AUTOSAR XML (schema 314)
package /ComponentType
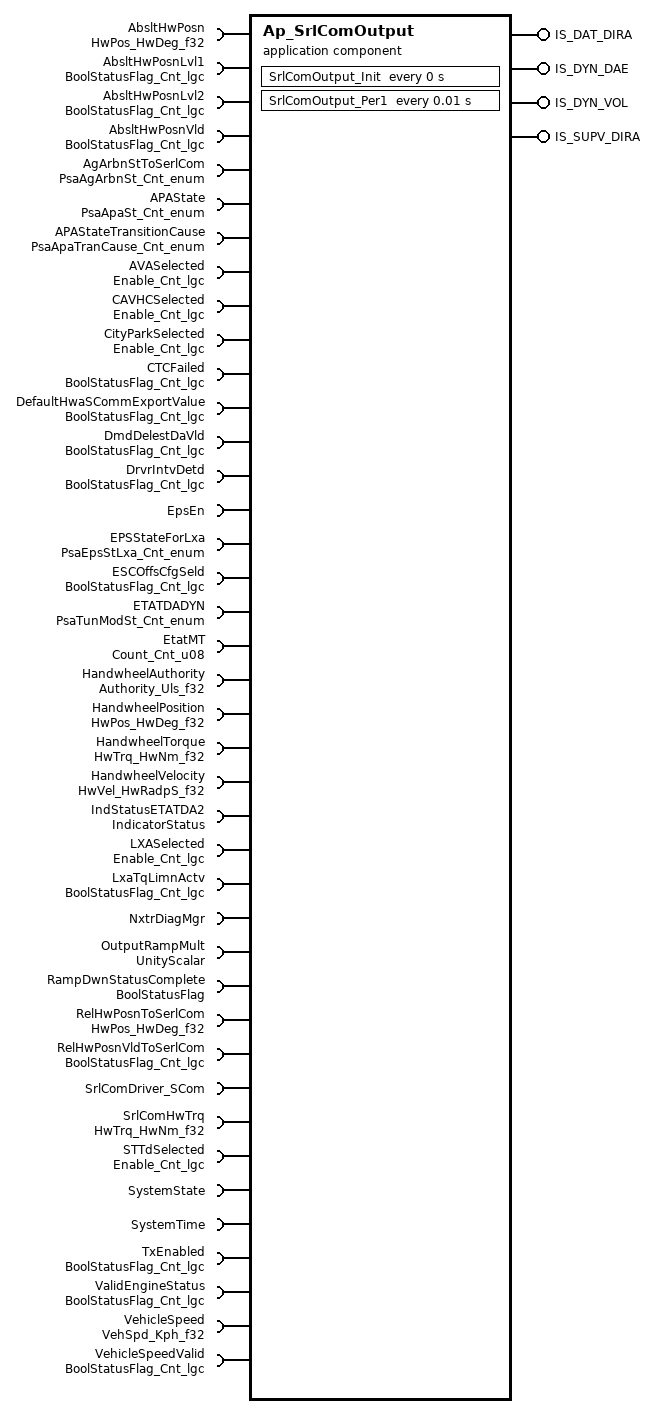
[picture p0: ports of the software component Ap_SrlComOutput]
  application software component type Ap_SrlComOutput
    4 x provide port, all with server-com-spec{operation=Get, queue-length=1}:
      IS_DAT_DIRA: provided-interface=IS_DAT_DIRA
      IS_DYN_DAE: provided-interface=IS_DYN_DAE
      IS_DYN_VOL: provided-interface=IS_DYN_VOL
      IS_SUPV_DIRA: provided-interface=IS_SUPV_DIRA
    40 x require port:
      AbsltHwPosn: unqueued-receiver-com-spec{data-element=HwDeg_f32, init-value=D_ZERO_ULS_F32}, required-interface=HwPos_HwDeg_f32
      AbsltHwPosnLvl1: unqueued-receiver-com-spec{data-element=Cnt_lgc, init-value=D_FALSE_CNT_LGC}, required-interface=BoolStatusFlag_Cnt_lgc
      AbsltHwPosnLvl2: unqueued-receiver-com-spec{data-element=Cnt_lgc, init-value=D_FALSE_CNT_LGC}, required-interface=BoolStatusFlag_Cnt_lgc
      AbsltHwPosnVld: unqueued-receiver-com-spec{data-element=Cnt_lgc, init-value=D_FALSE_CNT_LGC}, required-interface=BoolStatusFlag_Cnt_lgc
      AgArbnStToSerlCom: unqueued-receiver-com-spec{data-element=Cnt_enum, init-value=D_PSAAGARBNSTINIT_CNT_ENUM}, required-interface=PsaAgArbnSt_Cnt_enum
      APAState: unqueued-receiver-com-spec{data-element=Cnt_enum, init-value=D_PSAAPASTINIT_CNT_ENUM}, required-interface=PsaApaSt_Cnt_enum
      APAStateTransitionCause: unqueued-receiver-com-spec{data-element=Cnt_enum, init-value=D_PSAAPATRANCAUSEINIT_CNT_ENUM}, required-interface=PsaApaTranCause_Cnt_enum
      AVASelected: unqueued-receiver-com-spec{data-element=Cnt_lgc, init-value=D_FALSE_CNT_LGC}, required-interface=Enable_Cnt_lgc
      CAVHCSelected: unqueued-receiver-com-spec{data-element=Cnt_lgc, init-value=D_FALSE_CNT_LGC}, required-interface=Enable_Cnt_lgc
      CityParkSelected: unqueued-receiver-com-spec{data-element=Cnt_lgc, init-value=D_FALSE_CNT_LGC}, required-interface=Enable_Cnt_lgc
      CTCFailed: unqueued-receiver-com-spec{data-element=Cnt_lgc, init-value=D_FALSE_CNT_LGC}, required-interface=BoolStatusFlag_Cnt_lgc
      DefaultHwaSCommExportValue: unqueued-receiver-com-spec{data-element=Cnt_lgc, init-value=D_FALSE_CNT_LGC}, required-interface=BoolStatusFlag_Cnt_lgc
      DmdDelestDaVld: unqueued-receiver-com-spec{data-element=Cnt_lgc, init-value=D_FALSE_CNT_LGC}, required-interface=BoolStatusFlag_Cnt_lgc
      DrvrIntvDetd: unqueued-receiver-com-spec{data-element=Cnt_lgc, init-value=D_FALSE_CNT_LGC}, required-interface=BoolStatusFlag_Cnt_lgc
      EpsEn: client-com-spec=OP_GET, required-interface=EpsEn
      EPSStateForLxa: unqueued-receiver-com-spec{data-element=Cnt_enum, init-value=D_PSAEPSSTLXAINIT_CNT_ENUM}, required-interface=PsaEpsStLxa_Cnt_enum
      ESCOffsCfgSeld: unqueued-receiver-com-spec{data-element=Cnt_lgc, init-value=D_FALSE_CNT_LGC}, required-interface=BoolStatusFlag_Cnt_lgc
      ETATDADYN: unqueued-receiver-com-spec{data-element=Cnt_enum, init-value=D_PSATUNMODSTINIT_CNT_ENUM}, required-interface=PsaTunModSt_Cnt_enum
      EtatMT: unqueued-receiver-com-spec{data-element=Cnt_u08, init-value=D_ZERO_CNT_U8}, required-interface=Count_Cnt_u08
      HandwheelAuthority: unqueued-receiver-com-spec{data-element=Uls_f32, init-value=D_ZERO_ULS_F32}, required-interface=Authority_Uls_f32
      HandwheelPosition: unqueued-receiver-com-spec{data-element=HwDeg_f32, init-value=D_ZERO_ULS_F32}, required-interface=HwPos_HwDeg_f32
      HandwheelTorque: unqueued-receiver-com-spec{data-element=HwNm_f32, init-value=D_ZERO_ULS_F32}, required-interface=HwTrq_HwNm_f32
      HandwheelVelocity: unqueued-receiver-com-spec{data-element=HwRadpS_f32, init-value=D_ZERO_ULS_F32}, required-interface=HwVel_HwRadpS_f32
      IndStatusETATDA2: client-com-spec=GetIndicatorStatus, required-interface=IndicatorStatus
      LXASelected: unqueued-receiver-com-spec{data-element=Cnt_lgc, init-value=D_FALSE_CNT_LGC}, required-interface=Enable_Cnt_lgc
      LxaTqLimnActv: unqueued-receiver-com-spec{data-element=Cnt_lgc, init-value=D_FALSE_CNT_LGC}, required-interface=BoolStatusFlag_Cnt_lgc
      NxtrDiagMgr: required-com-specs=[GetNTCActive, GetNTCFailed, GetNTCStatus, SetNTCStatus], required-interface=NxtrDiagMgr
      OutputRampMult: unqueued-receiver-com-spec{data-element=Uls_f32, init-value=D_ZERO_ULS_F32}, required-interface=UnityScalar
      RampDwnStatusComplete: unqueued-receiver-com-spec{data-element=Cnt_lgc, init-value=D_FALSE_CNT_LGC}, required-interface=BoolStatusFlag
      RelHwPosnToSerlCom: unqueued-receiver-com-spec{data-element=HwDeg_f32, init-value=D_ZERO_ULS_F32}, required-interface=HwPos_HwDeg_f32
      RelHwPosnVldToSerlCom: unqueued-receiver-com-spec{data-element=Cnt_lgc, init-value=D_FALSE_CNT_LGC}, required-interface=BoolStatusFlag_Cnt_lgc
      SrlComDriver_SCom: required-com-specs=[ElecIntStart, ElecIntStop, GetBusOffCounter, SendMsgOnChange], required-interface=SrlComDriver_SCom
      SrlComHwTrq: unqueued-receiver-com-spec{data-element=HwNm_f32, init-value=D_ZERO_ULS_F32}, required-interface=HwTrq_HwNm_f32
      STTdSelected: unqueued-receiver-com-spec{data-element=Cnt_lgc, init-value=D_FALSE_CNT_LGC}, required-interface=Enable_Cnt_lgc
      SystemState: required-interface=SystemState
      SystemTime: required-interface=SystemTime
        required-com-specs:
          DtrmnElapsedTime_mS_u16
          DtrmnElapsedTime_mS_u32
          DtrmnElapsedTime_uS_u16
          DtrmnElapsedTime_uS_u32
          GetSystemTime_mS_u32
          GetSystemTime_uS_u32
      TxEnabled: unqueued-receiver-com-spec{data-element=Cnt_lgc, init-value=D_FALSE_CNT_LGC}, required-interface=BoolStatusFlag_Cnt_lgc
      ValidEngineStatus: unqueued-receiver-com-spec{data-element=Cnt_lgc, init-value=D_FALSE_CNT_LGC}, required-interface=BoolStatusFlag_Cnt_lgc
      VehicleSpeed: unqueued-receiver-com-spec{data-element=Kph_f32, init-value=D_ZERO_ULS_F32}, required-interface=VehSpd_Kph_f32
      VehicleSpeedValid: unqueued-receiver-com-spec{data-element=Cnt_lgc, init-value=D_FALSE_CNT_LGC}, required-interface=BoolStatusFlag_Cnt_lgc
  internal behavior Ap_SrlComOutput_InternalBehavior: component=Ap_SrlComOutput
    timing event SrlComOutput_InitEvent: start-on-event=SrlComOutput_Init, period=0
    4 x operation invoked event:
      OIT_SrlComOutput_IS_DAT_DIRA_Get_IS_DAT_DIRA_Get: start-on-event=SrlComOutput_IS_DAT_DIRA_Get, operation=IS_DAT_DIRA.Get
      OIT_SrlComOutput_IS_DYN_DAE_Get_IS_DYN_DAE_Get: start-on-event=SrlComOutput_IS_DYN_DAE_Get, operation=IS_DYN_DAE.Get
      OIT_SrlComOutput_IS_DYN_VOL_Get_IS_DYN_VOL_Get: start-on-event=SrlComOutput_IS_DYN_VOL_Get, operation=IS_DYN_VOL.Get
      OIT_SrlComOutput_IS_SUPV_DIRA_Get_IS_SUPV_DIRA_Get: start-on-event=SrlComOutput_IS_SUPV_DIRA_Get, operation=IS_SUPV_DIRA.Get
    timing event TMT_SrlComOutput_Per1: mode-dependency=dependent-on-mode=SystemState.Mode.OFF, start-on-event=SrlComOutput_Per1, period=0.01
    mode switch event MST_SrlComOutput_Trns1_0: start-on-event=SrlComOutput_Trns1, activation=EXIT, mode=SystemState.Mode.OFF
    4 x exclusive area:
      IsDatDiraMsg
      IsDynDaeMsg
      IsDynVolMsg
      IsSupvDiraMsg
    5 x per instance memory:
      PimIsDatDiraMsg: type=IS_DAT_DIRA_Msg, type-definition=/DataType/IS_DAT_DIRA_Msg
      PimIsDynDaeMsg: type=IS_DYN_DAE_Msg, type-definition=/DataType/IS_DYN_DAE_Msg
      PimIsDynVolAddMsg: type=IS_DYN_VOL_MsgAdd, type-definition=/DataType/IS_DYN_VOL_MsgAdd
      PimIsDynVolBaseMsg: type=IS_DYN_VOL_MsgBase, type-definition=/DataType/IS_DYN_VOL_MsgBase
      PimIsSupvDiraMsg: type=IS_SUPV_DIRA_Msg, type-definition=/DataType/IS_SUPV_DIRA_Msg
    port-api-options:
      enable-take-address=false, indirect-api=false, port=AbsltHwPosn
      enable-take-address=false, indirect-api=false, port=AbsltHwPosnLvl1
      enable-take-address=false, indirect-api=false, port=AbsltHwPosnLvl2
      enable-take-address=false, indirect-api=false, port=AbsltHwPosnVld
      enable-take-address=false, indirect-api=false, port=AgArbnStToSerlCom
      enable-take-address=false, indirect-api=false, port=APAState
      enable-take-address=false, indirect-api=false, port=APAStateTransitionCause
      enable-take-address=false, indirect-api=false, port=AVASelected
      enable-take-address=false, indirect-api=false, port=CAVHCSelected
      enable-take-address=false, indirect-api=false, port=CityParkSelected
      enable-take-address=false, indirect-api=false, port=CTCFailed
      enable-take-address=false, indirect-api=false, port=DefaultHwaSCommExportValue
      enable-take-address=false, indirect-api=false, port=DmdDelestDaVld
      enable-take-address=false, indirect-api=false, port=DrvrIntvDetd
      enable-take-address=false, indirect-api=false, port=EpsEn
      enable-take-address=false, indirect-api=false, port=EPSStateForLxa
      enable-take-address=false, indirect-api=false, port=ESCOffsCfgSeld
      enable-take-address=false, indirect-api=false, port=ETATDADYN
      enable-take-address=false, indirect-api=false, port=EtatMT
      enable-take-address=false, indirect-api=false, port=HandwheelAuthority
      enable-take-address=false, indirect-api=false, port=HandwheelPosition
      enable-take-address=false, indirect-api=false, port=HandwheelTorque
      enable-take-address=false, indirect-api=false, port=HandwheelVelocity
      enable-take-address=false, indirect-api=false, port=IndStatusETATDA2
      enable-take-address=false, indirect-api=false, port=IS_DAT_DIRA
      enable-take-address=false, indirect-api=false, port=IS_DYN_DAE
      enable-take-address=false, indirect-api=false, port=IS_DYN_VOL
      enable-take-address=false, indirect-api=false, port=IS_SUPV_DIRA
      enable-take-address=false, indirect-api=false, port=LXASelected
      enable-take-address=false, indirect-api=false, port=LxaTqLimnActv
      enable-take-address=false, indirect-api=false, port=NxtrDiagMgr
      enable-take-address=false, indirect-api=false, port=OutputRampMult
      enable-take-address=false, indirect-api=false, port=RampDwnStatusComplete
      enable-take-address=false, indirect-api=false, port=RelHwPosnToSerlCom
      enable-take-address=false, indirect-api=false, port=RelHwPosnVldToSerlCom
      enable-take-address=false, indirect-api=false, port=SrlComDriver_SCom
      enable-take-address=false, indirect-api=false, port=SrlComHwTrq
      enable-take-address=false, indirect-api=false, port=STTdSelected
      enable-take-address=false, indirect-api=false, port=SystemState
      enable-take-address=false, indirect-api=false, port=SystemTime
      enable-take-address=false, indirect-api=false, port=TxEnabled
      enable-take-address=false, indirect-api=false, port=ValidEngineStatus
      enable-take-address=false, indirect-api=false, port=VehicleSpeed
      enable-take-address=false, indirect-api=false, port=VehicleSpeedValid
    7 x runnable:
      SrlComOutput_Init
        sync call SC_SystemTime_GetSystemTime_mS_u32: operation=SystemTime.GetSystemTime_mS_u32, timeout=0
      SrlComOutput_IS_DAT_DIRA_Get: can-be-invoked-concurrently=true, can-enter-exclusive-area=IsDatDiraMsg
      SrlComOutput_IS_DYN_DAE_Get: can-be-invoked-concurrently=true, can-enter-exclusive-area=IsDynDaeMsg
      SrlComOutput_IS_DYN_VOL_Get: can-be-invoked-concurrently=true, can-enter-exclusive-area=IsDynVolMsg
      SrlComOutput_IS_SUPV_DIRA_Get: can-be-invoked-concurrently=true, can-enter-exclusive-area=IsSupvDiraMsg
      SrlComOutput_Per1: can-enter-exclusive-area=[IsDynDaeMsg, IsDatDiraMsg, IsSupvDiraMsg, IsDynVolMsg]
        33 x data read access:
          READ_AbsltHwPosn_HwDeg_f32: data-element=AbsltHwPosn.HwDeg_f32
          READ_AbsltHwPosnLvl1_Cnt_lgc: data-element=AbsltHwPosnLvl1.Cnt_lgc
          READ_AbsltHwPosnLvl2_Cnt_lgc: data-element=AbsltHwPosnLvl2.Cnt_lgc
          READ_AbsltHwPosnVld_Cnt_lgc: data-element=AbsltHwPosnVld.Cnt_lgc
          READ_AgArbnStToSerlCom_Cnt_enum: data-element=AgArbnStToSerlCom.Cnt_enum
          READ_APAState_Cnt_enum: data-element=APAState.Cnt_enum
          READ_APAStateTransitionCause_Cnt_enum: data-element=APAStateTransitionCause.Cnt_enum
          READ_AVASelected_Cnt_lgc: data-element=AVASelected.Cnt_lgc
          READ_CAVHCSelected_Cnt_lgc: data-element=CAVHCSelected.Cnt_lgc
          READ_CityParkSelected_Cnt_lgc: data-element=CityParkSelected.Cnt_lgc
          READ_CTCFailed_Cnt_lgc: data-element=CTCFailed.Cnt_lgc
          READ_DefaultHwaSCommExportValue_Cnt_lgc: data-element=DefaultHwaSCommExportValue.Cnt_lgc
          READ_DmdDelestDaVld_Cnt_lgc: data-element=DmdDelestDaVld.Cnt_lgc
          READ_DrvrIntvDetd_Cnt_lgc: data-element=DrvrIntvDetd.Cnt_lgc
          READ_EPSStateForLxa_Cnt_enum: data-element=EPSStateForLxa.Cnt_enum
          READ_ESCOffsCfgSeld_Cnt_lgc: data-element=ESCOffsCfgSeld.Cnt_lgc
          READ_ETATDADYN_Cnt_enum: data-element=ETATDADYN.Cnt_enum
          READ_EtatMT_Cnt_u08: data-element=EtatMT.Cnt_u08
          READ_HandwheelAuthority_Uls_f32: data-element=HandwheelAuthority.Uls_f32
          READ_HandwheelPosition_HwDeg_f32: data-element=HandwheelPosition.HwDeg_f32
          READ_HandwheelTorque_HwNm_f32: data-element=HandwheelTorque.HwNm_f32
          READ_HandwheelVelocity_HwRadpS_f32: data-element=HandwheelVelocity.HwRadpS_f32
          READ_LXASelected_Cnt_lgc: data-element=LXASelected.Cnt_lgc
          READ_LxaTqLimnActv_Cnt_lgc: data-element=LxaTqLimnActv.Cnt_lgc
          READ_OutputRampMult_Uls_f32: data-element=OutputRampMult.Uls_f32
          READ_RampDwnStatusComplete_Cnt_lgc: data-element=RampDwnStatusComplete.Cnt_lgc
          READ_RelHwPosnToSerlCom_HwDeg_f32: data-element=RelHwPosnToSerlCom.HwDeg_f32
          READ_RelHwPosnVldToSerlCom_Cnt_lgc: data-element=RelHwPosnVldToSerlCom.Cnt_lgc
          READ_SrlComHwTrq_HwNm_f32: data-element=SrlComHwTrq.HwNm_f32
          READ_STTdSelected_Cnt_lgc: data-element=STTdSelected.Cnt_lgc
          READ_ValidEngineStatus_Cnt_lgc: data-element=ValidEngineStatus.Cnt_lgc
          READ_VehicleSpeed_Kph_f32: data-element=VehicleSpeed.Kph_f32
          READ_VehicleSpeedValid_Cnt_lgc: data-element=VehicleSpeedValid.Cnt_lgc
        data receive point REC_TxEnabled_Cnt_lgc: data-element=TxEnabled.Cnt_lgc
        6 x sync call, all with timeout=0:
          SC_EpsEn_OP_GET: operation=EpsEn.OP_GET
          SC_IndStatusETATDA2_GetIndicatorStatus: operation=IndStatusETATDA2.GetIndicatorStatus
          SC_NxtrDiagMgr_GetNTCFailed: operation=NxtrDiagMgr.GetNTCFailed
          SC_SrlComDriver_SCom_SendMsgOnChange: operation=SrlComDriver_SCom.SendMsgOnChange
          SC_SystemTime_DtrmnElapsedTime_mS_u16: operation=SystemTime.DtrmnElapsedTime_mS_u16
          SC_SystemTime_GetSystemTime_mS_u32: operation=SystemTime.GetSystemTime_mS_u32
      SrlComOutput_Trns1
  swc implementation Ap_SrlComOutput_Implementation: behavior=Ap_SrlComOutput_InternalBehavior
    code-descriptors:
      code Code: type=SRC
